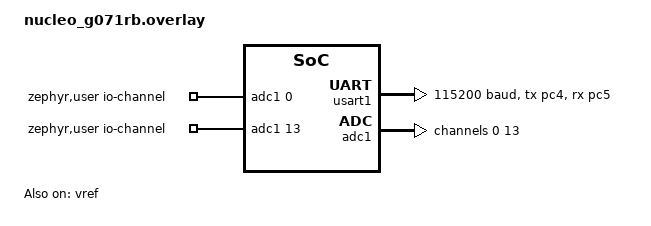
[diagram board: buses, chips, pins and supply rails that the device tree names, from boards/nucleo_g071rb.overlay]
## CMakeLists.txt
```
cmake_minimum_required(VERSION 3.20.0)

find_package(Zephyr REQUIRED HINTS $ENV{ZEPHYR_BASE})
project(stm32g0b1re_printf)

target_sources(app PRIVATE src/main.c)
```

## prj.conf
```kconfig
CONFIG_SERIAL=y
CONFIG_GPIO=y
CONFIG_PINCTRL_DYNAMIC=y
CONFIG_CONSOLE=y
CONFIG_UART_CONSOLE=y
CONFIG_STDOUT_CONSOLE=y
CONFIG_ADC=y
```

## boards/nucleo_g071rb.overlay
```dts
/ {
	aliases {
		spare-uart = &usart1;
	};

	zephyr,user {
		io-channels = <&adc1 0>, <&adc1 13>;
	};
};

&usart1 {
	pinctrl-0 = <&usart1_tx_pc4 &usart1_rx_pc5>;
	pinctrl-names = "default";
	current-speed = <115200>;
	status = "okay";
};

&usart1_rx_pc5 {
	bias-pull-up;
};

&adc1 {
	#address-cells = <1>;
	#size-cells = <0>;

	channel@0 {
		reg = <0>;
		zephyr,gain = "ADC_GAIN_1";
		zephyr,reference = "ADC_REF_INTERNAL";
		zephyr,acquisition-time = <ADC_ACQ_TIME_MAX>;
		zephyr,resolution = <12>;
	};

	channel@d {
		reg = <13>;
		zephyr,gain = "ADC_GAIN_1";
		zephyr,reference = "ADC_REF_INTERNAL";
		zephyr,acquisition-time = <ADC_ACQ_TIME_MAX>;
		zephyr,resolution = <12>;
	};
};

&vref {
	status = "okay";
};
```

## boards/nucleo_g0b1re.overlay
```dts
/ {
	chosen {
		/delete-property/ zephyr,canbus;
	};

	aliases {
		spare-uart = &usart1;
	};

	zephyr,user {
		io-channels = <&adc1 0>, <&adc1 13>;
	};
};

&zephyr_udc0 {
	status = "disabled";
};

&usart1 {
	pinctrl-0 = <&usart1_tx_pc4 &usart1_rx_pc5>;
	pinctrl-names = "default";
	current-speed = <115200>;
	status = "okay";
};

&usart1_rx_pc5 {
	bias-pull-up;
};

&rtc {
	status = "disabled";
};

&iwdg {
	status = "disabled";
};

&timers3 {
	status = "disabled";
};

&pwm3 {
	status = "disabled";
};

&timers15 {
	status = "disabled";
};

&pwm15 {
	status = "disabled";
};

&i2c1 {
	status = "disabled";
};

&i2c2 {
	status = "disabled";
};

&spi1 {
	status = "disabled";
};

&spi2 {
	status = "disabled";
};

&adc1 {
	#address-cells = <1>;
	#size-cells = <0>;
	status = "okay";

	channel@0 {
		reg = <0>;
		zephyr,gain = "ADC_GAIN_1";
		zephyr,reference = "ADC_REF_INTERNAL";
		zephyr,acquisition-time = <ADC_ACQ_TIME_MAX>;
		zephyr,resolution = <12>;
	};

	channel@d {
		reg = <13>;
		zephyr,gain = "ADC_GAIN_1";
		zephyr,reference = "ADC_REF_INTERNAL";
		zephyr,acquisition-time = <ADC_ACQ_TIME_MAX>;
		zephyr,resolution = <12>;
	};
};

&die_temp {
	status = "disabled";
};

&dac1 {
	status = "disabled";
};

&fdcan1 {
	status = "disabled";
};

&fdcan2 {
	status = "disabled";
};

&vref {
	status = "okay";
};

&vbat {
	status = "disabled";
};
```

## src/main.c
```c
#include <inttypes.h>
#include <stdint.h>
#include <stdio.h>

#include <zephyr/devicetree.h>
#include <zephyr/drivers/adc.h>
#include <zephyr/kernel.h>
#include <zephyr/sys/util.h>

#include <stm32g0xx_ll_adc.h>

#define APP_NODE DT_PATH(zephyr_user)
#define ADC_VREFINT_NODE DT_IO_CHANNELS_CTLR_BY_IDX(APP_NODE, 1)
#define ADC_VREFINT_BASE ((ADC_TypeDef *)DT_REG_ADDR(ADC_VREFINT_NODE))

#if !DT_NODE_EXISTS(APP_NODE) || !DT_NODE_HAS_PROP(APP_NODE, io_channels)
#error "zephyr,user io-channels must be defined in the board overlay"
#endif

static const struct adc_dt_spec adc_pa0 = ADC_DT_SPEC_GET_BY_IDX(APP_NODE, 0);
static const struct adc_dt_spec adc_vrefint = ADC_DT_SPEC_GET_BY_IDX(APP_NODE, 1);

static void enable_vrefint_channel(void)
{
	uint32_t path = LL_ADC_GetCommonPathInternalCh(__LL_ADC_COMMON_INSTANCE(ADC_VREFINT_BASE));

	LL_ADC_SetCommonPathInternalCh(__LL_ADC_COMMON_INSTANCE(ADC_VREFINT_BASE),
				       path | LL_ADC_PATH_INTERNAL_VREFINT);
#ifdef LL_ADC_DELAY_VREFINT_STAB_US
	k_usleep(LL_ADC_DELAY_VREFINT_STAB_US);
#endif
}

static void disable_vrefint_channel(void)
{
	uint32_t path = LL_ADC_GetCommonPathInternalCh(__LL_ADC_COMMON_INSTANCE(ADC_VREFINT_BASE));

	LL_ADC_SetCommonPathInternalCh(__LL_ADC_COMMON_INSTANCE(ADC_VREFINT_BASE),
				       path & ~LL_ADC_PATH_INTERNAL_VREFINT);
}

static int read_adc_raw(const struct adc_dt_spec *spec, int16_t *raw)
{
	struct adc_sequence sequence = {
		.buffer = raw,
		.buffer_size = sizeof(*raw),
	};

	*raw = 0;
	adc_sequence_init_dt(spec, &sequence);
	return adc_read_dt(spec, &sequence);
}

static uint32_t adc_full_scale(const struct adc_dt_spec *spec)
{
	return BIT(spec->resolution) - 1U;
}

static uint32_t calc_vdda_mv(uint16_t vrefint_raw)
{
	if (vrefint_raw == 0U) {
		return 0U;
	}

	/*
	 * ST formula:
	 * VDDA(mV) = VREFINT_CAL_VREF(mV) * VREFINT_CAL / VREFINT_RAW
	 */
	return (((uint32_t)(*VREFINT_CAL_ADDR) * VREFINT_CAL_VREF) + (vrefint_raw / 2U))
	       / vrefint_raw;
}

static uint32_t calc_input_mv(uint16_t input_raw, uint32_t vdda_mv, uint32_t full_scale)
{
	if (full_scale == 0U) {
		return 0U;
	}

	/*
	 * Input(mV) = RAW * VDDA(mV) / ((2 ^ resolution) - 1)
	 */
	return (((uint32_t)input_raw * vdda_mv) + (full_scale / 2U)) / full_scale;
}

int main(void)
{
	int err;
	int16_t pa0_raw;
	int16_t vrefint_raw;

	printf("STM32G0 ADC PA0 monitor\r\n");
	printf("Board: %s\r\n", CONFIG_BOARD_TARGET);
	printf("Formula: VDDA = 3000mV * VREFINT_CAL / VREFINT_RAW\r\n");
	printf("Formula: PA0  = PA0_RAW * VDDA / 4095\r\n");

	if (!adc_is_ready_dt(&adc_pa0) || !adc_is_ready_dt(&adc_vrefint)) {
		printf("ADC device is not ready\r\n");
		return 0;
	}

	err = adc_channel_setup_dt(&adc_pa0);
	if (err < 0) {
		printf("Failed to setup PA0 ADC channel: %d\r\n", err);
		return 0;
	}

	err = adc_channel_setup_dt(&adc_vrefint);
	if (err < 0) {
		printf("Failed to setup VREFINT ADC channel: %d\r\n", err);
		return 0;
	}

	while (1) {
		uint32_t vdda_mv;
		uint32_t pa0_mv;

		enable_vrefint_channel();
		err = read_adc_raw(&adc_vrefint, &vrefint_raw);
		disable_vrefint_channel();
		if (err < 0) {
			printf("Failed to read VREFINT: %d\r\n", err);
			k_sleep(K_SECONDS(1));
			continue;
		}

		err = read_adc_raw(&adc_pa0, &pa0_raw);
		if (err < 0) {
			printf("Failed to read PA0: %d\r\n", err);
			k_sleep(K_SECONDS(1));
			continue;
		}

		vdda_mv = calc_vdda_mv((uint16_t)vrefint_raw);
		pa0_mv = calc_input_mv((uint16_t)pa0_raw, vdda_mv, adc_full_scale(&adc_pa0));

		printf("PA0 raw=%" PRIu16 ", VREFINT raw=%" PRIu16
		       ", VDDA=%" PRIu32 " mV, PA0=%" PRIu32 ".%03" PRIu32 " V\r\n",
		       (uint16_t)pa0_raw, (uint16_t)vrefint_raw,
		       vdda_mv, pa0_mv / 1000U, pa0_mv % 1000U);

		k_sleep(K_SECONDS(1));
	}

	return 0;
}
```
